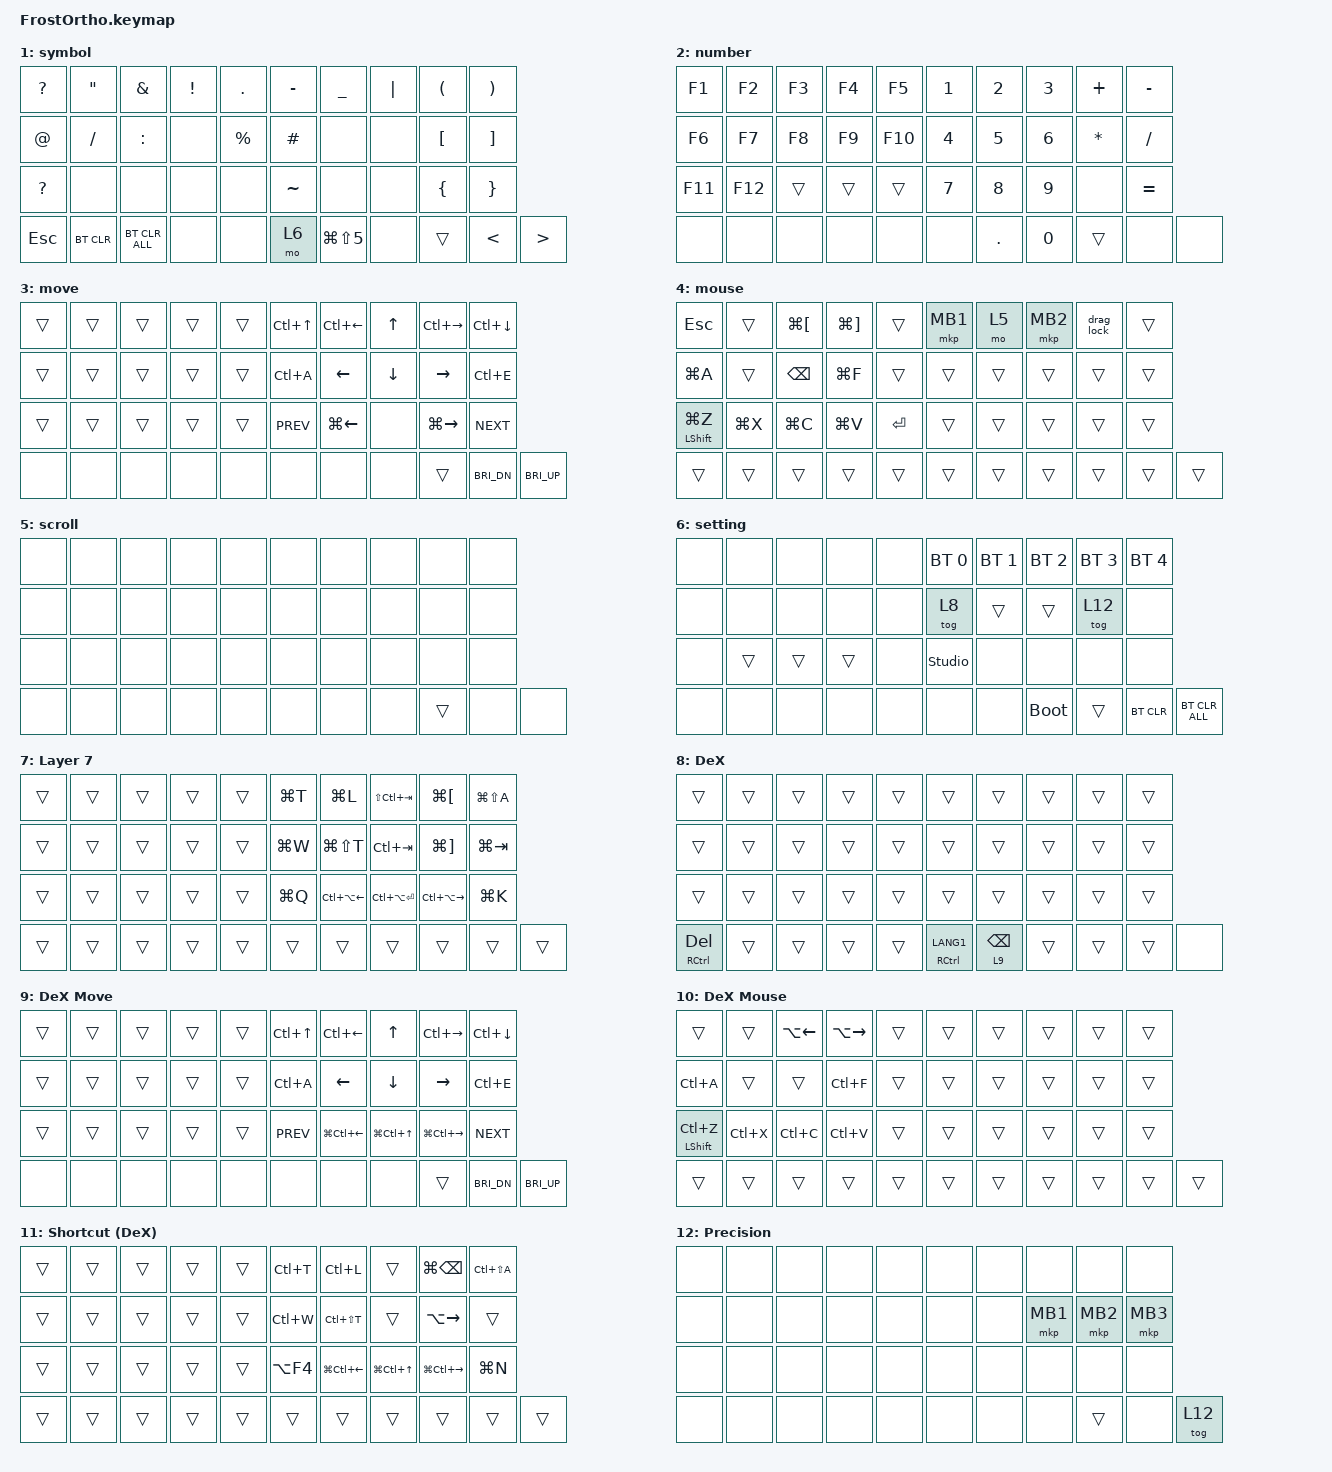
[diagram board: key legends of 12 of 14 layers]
// FrostOrtho keymap — Conductor Monokey から移植
// このファイルは自動生成です(元データ: Conductor の書き出しJSON + FrostOrtho用の変更)
#include <input/processors.dtsi>
#include <behaviors/runtime-sensor-rotate.dtsi>
#include <behaviors.dtsi>
#include <dt-bindings/zmk/bt.h>
#include <dt-bindings/zmk/keys.h>
#include <dt-bindings/zmk/pointing.h>

&mt {
    flavor = "balanced";
    quick-tap-ms = <0>;
};

// AML(レイヤー4)中にクリックしたらタイムアウトを延長
&mkp_input_listener { input-processors = <&zip_temp_layer 4 10000>; };

/ {
    combos {
        compatible = "zmk,combos";
        combo_0 {
            timeout-ms = <50>;
            key-positions = <17 18>;
            bindings = <&mo 5>;
        };  // L5
        combo_1 {
            timeout-ms = <50>;
            key-positions = <7 8>;
            bindings = <&mo 13>;
        };  // L13
        combo_4 {
            timeout-ms = <50>;
            key-positions = <0 10 20>;
            bindings = <&bt BT_SEL 5>;
        };  // BT 5
        combo_5 {
            timeout-ms = <50>;
            key-positions = <8 24 4>;
            bindings = <&bootloader>;
        };  // Boot
    };

    // マウス中(4) かつ DeXモード中(8) は、DeX用の編集キー(10)を重ねる
    conditional_layers {
        compatible = "zmk,conditional-layers";
        dex_mouse {
            if-layers = <4 8>;
            then-layer = <10>;
        };
        // ショートカット中(7) かつ DeXモード中(8) は、Fold8用のショートカット(11)を重ねる
        dex_shortcut {
            if-layers = <7 8>;
            then-layer = <11>;
        };
    };

    behaviors {
        // Bksp用レイヤータップ: タップ→すぐ押し直して長押しでBksp連打
        lt_bspc: lt_bspc {
            compatible = "zmk,behavior-hold-tap";
            #binding-cells = <2>;
            flavor = "tap-preferred";
            tapping-term-ms = <200>;
            quick-tap-ms = <200>;
            bindings = <&mo>, <&kp>;
        };

        // ドラッグ固定: 押すと左クリックを押しっぱなしに、もう一度で離す(マウスレイヤーを出ても自動で離す)
        drag_lock: drag_lock {
            compatible = "zmk,behavior-frost-drag-lock";
            #binding-cells = <0>;
        };

        // エンコーダー(DYA Studioからも変更可)
        // スクロール量 = 速さ(1500) × 時間(32ms)
        rsr_scroll: rsr_scroll {
            compatible = "zmk,behavior-runtime-sensor-rotate";
            #sensor-binding-cells = <0>;
            tap-ms = <32>;
            cw-binding = <&msc MOVE_Y(-1500)>;
            ccw-binding = <&msc MOVE_Y(1500)>;
        };
        rsr_vol: rsr_vol {
            compatible = "zmk,behavior-runtime-sensor-rotate";
            #sensor-binding-cells = <0>;
            tap-ms = <5>;
            cw-binding = <&kp C_VOL_DN>;
            ccw-binding = <&kp C_VOL_UP>;
        };
        rsr_tab: rsr_tab {
            compatible = "zmk,behavior-runtime-sensor-rotate";
            #sensor-binding-cells = <0>;
            tap-ms = <5>;
            cw-binding = <&kp LC(TAB)>;
            ccw-binding = <&kp LS(LC(TAB))>;
        };
        rsr_zoom: rsr_zoom {
            compatible = "zmk,behavior-runtime-sensor-rotate";
            #sensor-binding-cells = <0>;
            tap-ms = <5>;
            cw-binding = <&kp LG(MINUS)>;
            ccw-binding = <&kp LG(EQUAL)>;
        };
    };

    keymap {
        compatible = "zmk,keymap";

        layer_0 {
            display-name = "base";
            bindings = <
&kp Q               &kp W               &kp E               &kp R               &kp T                   &kp Y               &kp U               &kp I               &kp O               &kp P               
&kp A               &kp S               &kp D               &kp F               &kp G                   &kp H               &kp J               &kp K               &kp L               &kp MINUS           
&mt LSHIFT Z        &kp X               &kp C               &kp V               &kp B                   &kp N               &kp M               &kp COMMA           &kp DOT             &mt RSHIFT FSLH     
&mt RGUI DEL        &lt 6 TAB           &kp LALT            &lt 1 LANG2         &lt 2 SPACE         &mt RGUI LANG1          &lt_bspc 3 BSPC     &lt 7 ENTER         &caps_word          &kp F13             &kp LG(LC(LS(N4)))  
            >;
            sensor-bindings = <&rsr_scroll>;
        };

        layer_1 {
            display-name = "symbol";
            bindings = <
&kp QMARK       &kp DQT         &kp AMPS        &kp EXCL        &kp DOT             &kp MINUS       &kp UNDER       &kp PIPE        &kp LPAR        &kp RPAR        
&kp AT          &kp FSLH        &kp COLON       &none           &kp PRCNT           &kp HASH        &none           &none           &kp LBKT        &kp RBKT        
&kp QMARK       &none           &none           &none           &none               &kp TILDE       &none           &none           &kp LBRC        &kp RBRC        
&kp ESC         &bt BT_CLR      &bt BT_CLR_ALL  &none           &none           &mo 6               &kp LG(LS(N5))  &none           &trans          &kp LT          &kp GT          
            >;
            sensor-bindings = <&rsr_zoom>;
        };

        layer_2 {
            display-name = "number";
            bindings = <
&kp F1     &kp F2     &kp F3     &kp F4     &kp F5         &kp N1     &kp N2     &kp N3     &kp PLUS   &kp MINUS  
&kp F6     &kp F7     &kp F8     &kp F9     &kp F10        &kp N4     &kp N5     &kp N6     &kp STAR   &kp FSLH   
&kp F11    &kp F12    &trans     &trans     &trans         &kp N7     &kp N8     &kp N9     &none      &kp EQUAL  
&none      &none      &none      &none      &none      &none          &kp DOT    &kp N0     &trans     &none      &none      
            >;
            sensor-bindings = <&rsr_vol>;
        };

        layer_3 {
            display-name = "move";
            bindings = <
&trans         &trans         &trans         &trans         &trans             &kp LC(UP)     &kp LC(LEFT)   &kp UP         &kp LC(RIGHT)  &kp LC(DOWN)   
&trans         &trans         &trans         &trans         &trans             &kp LC(A)      &kp LEFT       &kp DOWN       &kp RIGHT      &kp LC(E)      
&trans         &trans         &trans         &trans         &trans             &kp C_PREV     &kp LG(LEFT)   &none          &kp LG(RIGHT)  &kp C_NEXT     
&none          &none          &none          &none          &none          &none              &none          &none          &trans         &kp C_BRI_DN   &kp C_BRI_UP   
            >;
            sensor-bindings = <&rsr_tab>;
        };

        layer_4 {
            display-name = "mouse";
            bindings = <
&kp ESC           &trans            &kp LG(LBKT)      &kp LG(RBKT)      &trans                &mkp MB1          &mo 5             &mkp MB2          &drag_lock        &trans            
&kp LG(A)         &trans            &kp BSPC          &kp LG(F)         &trans                &trans            &trans            &trans            &trans            &trans            
&mt LSHIFT LG(Z)  &kp LG(X)         &kp LG(C)         &kp LG(V)         &kp RET               &trans            &trans            &trans            &trans            &trans            
&trans            &trans            &trans            &trans            &trans            &trans                &trans            &trans            &trans            &trans            &trans            
            >;
            sensor-bindings = <&rsr_trans>;
        };

        layer_5 {
            display-name = "scroll";
            bindings = <
&none   &none   &none   &none   &none       &none   &none   &none   &none   &none   
&none   &none   &none   &none   &none       &none   &none   &none   &none   &none   
&none   &none   &none   &none   &none       &none   &none   &none   &none   &none   
&none   &none   &none   &none   &none   &none       &none   &none   &trans  &none   &none   
            >;
            sensor-bindings = <&rsr_trans>;
        };

        layer_6 {
            display-name = "setting";
            bindings = <
&none           &none           &none           &none           &none               &bt BT_SEL 0    &bt BT_SEL 1    &bt BT_SEL 2    &bt BT_SEL 3    &bt BT_SEL 4    
&none           &none           &none           &none           &none               &tog 8          &trans          &trans          &tog 12         &none           
&none           &trans          &trans          &trans          &none               &studio_unlock  &none           &none           &none           &none           
&none           &none           &none           &none           &none           &none               &none           &bootloader     &trans          &bt BT_CLR      &bt BT_CLR_ALL  
            >;
            sensor-bindings = <&rsr_trans>;
        };

        layer_7 {
            display-name = "Layer 7";
            bindings = <
&trans             &trans             &trans             &trans             &trans                 &kp LG(T)          &kp LG(L)          &kp LS(LC(TAB))    &kp LG(LBKT)       &kp LG(LS(A))      
&trans             &trans             &trans             &trans             &trans                 &kp LG(W)          &kp LG(LS(T))      &kp LC(TAB)        &kp LG(RBKT)       &kp LG(TAB)        
&trans             &trans             &trans             &trans             &trans                 &kp LG(Q)          &kp LC(LA(LEFT))   &kp LC(LA(RET))    &kp LC(LA(RIGHT))  &kp LG(K)          
&trans             &trans             &trans             &trans             &trans             &trans                 &trans             &trans             &trans             &trans             &trans             
            >;
            sensor-bindings = <&rsr_trans>;
        };

        layer_8 {
            display-name = "DeX";
            bindings = <
&trans           &trans           &trans           &trans           &trans               &trans           &trans           &trans           &trans           &trans           
&trans           &trans           &trans           &trans           &trans               &trans           &trans           &trans           &trans           &trans           
&trans           &trans           &trans           &trans           &trans               &trans           &trans           &trans           &trans           &trans           
&mt RCTRL DEL    &trans           &trans           &trans           &trans           &mt RCTRL LANG1      &lt_bspc 9 BSPC  &trans           &trans           &trans           &none            
            >;
            sensor-bindings = <&rsr_trans>;
        };

        layer_9 {
            display-name = "DeX Move";
            bindings = <
&trans             &trans             &trans             &trans             &trans                 &kp LC(UP)         &kp LC(LEFT)       &kp UP             &kp LC(RIGHT)      &kp LC(DOWN)       
&trans             &trans             &trans             &trans             &trans                 &kp LC(A)          &kp LEFT           &kp DOWN           &kp RIGHT          &kp LC(E)          
&trans             &trans             &trans             &trans             &trans                 &kp C_PREV         &kp LG(LC(LEFT))   &kp LG(LC(UP))     &kp LG(LC(RIGHT))  &kp C_NEXT         
&none              &none              &none              &none              &none              &none                  &none              &none              &trans             &kp C_BRI_DN       &kp C_BRI_UP       
            >;
            sensor-bindings = <&rsr_trans>;
        };

        layer_10 {
            display-name = "DeX Mouse";
            bindings = <
&trans            &trans            &kp LA(LEFT)      &kp LA(RIGHT)     &trans                &trans            &trans            &trans            &trans            &trans            
&kp LC(A)         &trans            &trans            &kp LC(F)         &trans                &trans            &trans            &trans            &trans            &trans            
&mt LSHIFT LC(Z)  &kp LC(X)         &kp LC(C)         &kp LC(V)         &trans                &trans            &trans            &trans            &trans            &trans            
&trans            &trans            &trans            &trans            &trans            &trans                &trans            &trans            &trans            &trans            &trans            
            >;
            sensor-bindings = <&rsr_trans>;
        };

        layer_11 {
            display-name = "Shortcut (DeX)";
            bindings = <
&trans             &trans             &trans             &trans             &trans                 &kp LC(T)          &kp LC(L)          &trans             &kp LG(BSPC)       &kp LC(LS(A))      
&trans             &trans             &trans             &trans             &trans                 &kp LC(W)          &kp LC(LS(T))      &trans             &kp LA(RIGHT)      &trans             
&trans             &trans             &trans             &trans             &trans                 &kp LA(F4)         &kp LG(LC(LEFT))   &kp LG(LC(UP))     &kp LG(LC(RIGHT))  &kp LG(N)          
&trans             &trans             &trans             &trans             &trans             &trans                 &trans             &trans             &trans             &trans             &trans             
            >;
            sensor-bindings = <&rsr_trans>;
        };

        layer_12 {
            display-name = "Precision";
            bindings = <
&none     &none     &none     &none     &none         &none     &none     &none     &none     &none     
&none     &none     &none     &none     &none         &none     &none     &mkp MB1  &mkp MB2  &mkp MB3  
&none     &none     &none     &none     &none         &none     &none     &none     &none     &none     
&none     &none     &none     &none     &none     &none         &none     &none     &trans    &none     &tog 12   
            >;
            sensor-bindings = <&rsr_trans>;
        };

        layer_13 {
            display-name = "Gesture";
            bindings = <
&none          &none          &none          &none          &none              &none          &none          &kp LC(DOWN)   &none          &none          
&none          &none          &none          &none          &none              &none          &kp LC(RIGHT)  &none          &kp LC(LEFT)   &none          
&none          &none          &none          &none          &none              &none          &none          &kp LC(UP)     &none          &none          
&none          &none          &none          &none          &none          &none              &none          &none          &trans         &none          &none          
            >;
            sensor-bindings = <&rsr_trans>;
        };
    };
};
